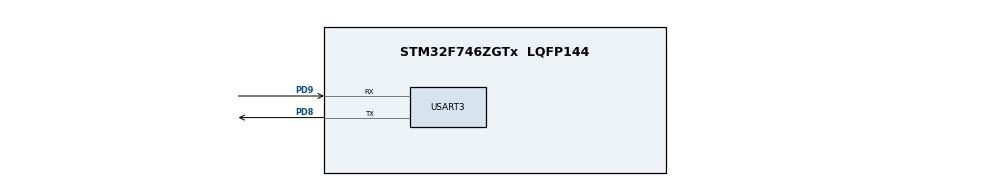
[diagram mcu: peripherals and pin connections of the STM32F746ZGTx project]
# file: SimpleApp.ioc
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CORTEX_M7.default_mode_Activation=1
Mcu.Family=STM32F7
Mcu.Name=STM32F746ZGTx
Mcu.Package=LQFP144
NVIC.PriorityGroup=NVIC_PRIORITYGROUP_4
PD8.Mode=Asynchronous
PD8.Signal=USART3_TX
PD9.Mode=Asynchronous
PD9.Signal=USART3_RX
ProjectManager.HeapSize=0x200
ProjectManager.StackSize=0x400
ProjectManager.TargetToolchain=CMake
RCC.HSE_VALUE=25000000
RCC.HSI_VALUE=16000000
RCC.LSE_VALUE=32768
RCC.USBFreq_Value=96000000
RCC.VCOOutputFreq_Value=192000000
USART3.VirtualMode-Asynchronous=VM_ASYNC
board=custom

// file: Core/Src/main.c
/* USER CODE BEGIN Header */
/**
  ******************************************************************************
  * @file           : main.c
  * @brief          : Main program body
  ******************************************************************************
  * @attention
  *
  * Copyright (c) 2026 STMicroelectronics.
  * All rights reserved.
  *
  * This software is licensed under terms that can be found in the LICENSE file
  * in the root directory of this software component.
  * If no LICENSE file comes with this software, it is provided AS-IS.
  *
  ******************************************************************************
  */
/* USER CODE END Header */
#include "main.h"

/* USER CODE BEGIN Includes */
#include "cmsis_gcc.h"
#include "stm32f7xx_hal.h"
#include <stdio.h>

/* USER CODE END Includes */

/* USER CODE BEGIN PTD */

#define STRUCT_PACKED struct __attribute__((__packed__))

STRUCT_PACKED image_version {
    uint8_t iv_major;
    uint8_t iv_minor;
    uint16_t iv_revision;
    uint32_t iv_build_num;
};

STRUCT_PACKED image_header {
    uint32_t ih_magic;
    uint32_t ih_load_addr;
    uint16_t ih_hdr_size;               /* Size of image header (bytes). */
    uint16_t ih_protect_tlv_size;       /* Size of protected TLV area (bytes). */
    uint32_t ih_img_size;               /* Does not include header. */
    uint32_t ih_flags;                  /* IMAGE_F_[...]. */
    struct image_version ih_ver;
    uint32_t _pad1;
};
/* USER CODE END PTD */

UART_HandleTypeDef huart3;

__attribute__((section("my_header"))) struct image_header header = {
    .ih_magic = 0x96f3b83d,
    .ih_load_addr = 0, // usata solo se l'immagine vine caricata in RAM
    .ih_hdr_size = 512,
    .ih_protect_tlv_size = 0, // non è lo stesso tlv che è presente alla fine dell'immagine
    .ih_img_size = 0x12000,
    .ih_flags = 0,
    .ih_ver = {
      .iv_major = 1,
      .iv_minor = 1,
      .iv_revision = 0,
      .iv_build_num = 0
    },

};

void SystemClock_Config(void);
static void MPU_Config(void);
static void MX_GPIO_Init(void);
static void MX_USART3_UART_Init(void);

/* USER CODE BEGIN 0 */

int _write(int file, char* ptr, int len){
  int DataIdx;

  for (DataIdx = 0; DataIdx < len; DataIdx++)
  {
    HAL_UART_Transmit(&huart3, (uint8_t* )ptr++,1,100);

  }

  return len;

}
/* USER CODE END 0 */

int main(void)
{

  /* MPU Configuration--------------------------------------------------------*/
  MPU_Config();

  /* MCU Configuration--------------------------------------------------------*/

  /* Reset of all peripherals, Initializes the Flash interface and the Systick. */
  HAL_Init();

  /* Configure the system clock */
  SystemClock_Config();

  /* Initialize all configured peripherals */
  MX_GPIO_Init();
  MX_USART3_UART_Init();

  /* Infinite loop */
  /* USER CODE BEGIN WHILE */
  printf("APP  ----  1 \r\n");
  HAL_Delay(100);
  while (1)
  {
    /* USER CODE END WHILE */

  }
}

void SystemClock_Config(void)
{
  RCC_OscInitTypeDef RCC_OscInitStruct = {0};
  RCC_ClkInitTypeDef RCC_ClkInitStruct = {0};

  /** Configure the main internal regulator output voltage
  */
  __HAL_RCC_PWR_CLK_ENABLE();
  __HAL_PWR_VOLTAGESCALING_CONFIG(PWR_REGULATOR_VOLTAGE_SCALE3);

  /** Initializes the RCC Oscillators according to the specified parameters
  * in the RCC_OscInitTypeDef structure.
  */
  RCC_OscInitStruct.OscillatorType = RCC_OSCILLATORTYPE_HSI;
  RCC_OscInitStruct.HSIState = RCC_HSI_ON;
  RCC_OscInitStruct.HSICalibrationValue = RCC_HSICALIBRATION_DEFAULT;
  RCC_OscInitStruct.PLL.PLLState = RCC_PLL_NONE;
  if (HAL_RCC_OscConfig(&RCC_OscInitStruct) != HAL_OK)
  {
    Error_Handler();
  }

  /** Initializes the CPU, AHB and APB buses clocks
  */
  RCC_ClkInitStruct.ClockType = RCC_CLOCKTYPE_HCLK|RCC_CLOCKTYPE_SYSCLK
                              |RCC_CLOCKTYPE_PCLK1|RCC_CLOCKTYPE_PCLK2;
  RCC_ClkInitStruct.SYSCLKSource = RCC_SYSCLKSOURCE_HSI;
  RCC_ClkInitStruct.AHBCLKDivider = RCC_SYSCLK_DIV1;
  RCC_ClkInitStruct.APB1CLKDivider = RCC_HCLK_DIV1;
  RCC_ClkInitStruct.APB2CLKDivider = RCC_HCLK_DIV1;

  if (HAL_RCC_ClockConfig(&RCC_ClkInitStruct, FLASH_LATENCY_0) != HAL_OK)
  {
    Error_Handler();
  }
}

static void MX_USART3_UART_Init(void)
{

  huart3.Instance = USART3;
  huart3.Init.BaudRate = 115200;
  huart3.Init.WordLength = UART_WORDLENGTH_8B;
  huart3.Init.StopBits = UART_STOPBITS_1;
  huart3.Init.Parity = UART_PARITY_NONE;
  huart3.Init.Mode = UART_MODE_TX_RX;
  huart3.Init.HwFlowCtl = UART_HWCONTROL_NONE;
  huart3.Init.OverSampling = UART_OVERSAMPLING_16;
  huart3.Init.OneBitSampling = UART_ONE_BIT_SAMPLE_DISABLE;
  huart3.AdvancedInit.AdvFeatureInit = UART_ADVFEATURE_NO_INIT;
  if (HAL_UART_Init(&huart3) != HAL_OK)
  {
    Error_Handler();
  }

}

static void MX_GPIO_Init(void)
{

  /* GPIO Ports Clock Enable */
  __HAL_RCC_GPIOD_CLK_ENABLE();

  /* USER CODE BEGIN MX_GPIO_Init_2 */
  GPIO_InitTypeDef GPIO_InitStruct = {0};

  GPIO_InitStruct.Pin = GPIO_PIN_13;
  GPIO_InitStruct.Mode = GPIO_MODE_OUTPUT_PP;
  GPIO_InitStruct.Pull = GPIO_NOPULL;
  GPIO_InitStruct.Speed = GPIO_SPEED_FREQ_LOW;

  HAL_GPIO_Init(GPIOG, &GPIO_InitStruct);
  /* USER CODE END MX_GPIO_Init_2 */
}

 /* MPU Configuration */

void MPU_Config(void)
{
  MPU_Region_InitTypeDef MPU_InitStruct = {0};

  /* Disables the MPU */
  HAL_MPU_Disable();

  /** Initializes and configures the Region and the memory to be protected
  */
  MPU_InitStruct.Enable = MPU_REGION_ENABLE;
  MPU_InitStruct.Number = MPU_REGION_NUMBER0;
  MPU_InitStruct.BaseAddress = 0x0;
  MPU_InitStruct.Size = MPU_REGION_SIZE_4GB;
  MPU_InitStruct.SubRegionDisable = 0x87;
  MPU_InitStruct.TypeExtField = MPU_TEX_LEVEL0;
  MPU_InitStruct.AccessPermission = MPU_REGION_NO_ACCESS;
  MPU_InitStruct.DisableExec = MPU_INSTRUCTION_ACCESS_DISABLE;
  MPU_InitStruct.IsShareable = MPU_ACCESS_SHAREABLE;
  MPU_InitStruct.IsCacheable = MPU_ACCESS_NOT_CACHEABLE;
  MPU_InitStruct.IsBufferable = MPU_ACCESS_NOT_BUFFERABLE;

  HAL_MPU_ConfigRegion(&MPU_InitStruct);
  /* Enables the MPU */
  HAL_MPU_Enable(MPU_PRIVILEGED_DEFAULT);

}

void Error_Handler(void)
{
  __disable_irq();
  while (1)
  {
  }
}
